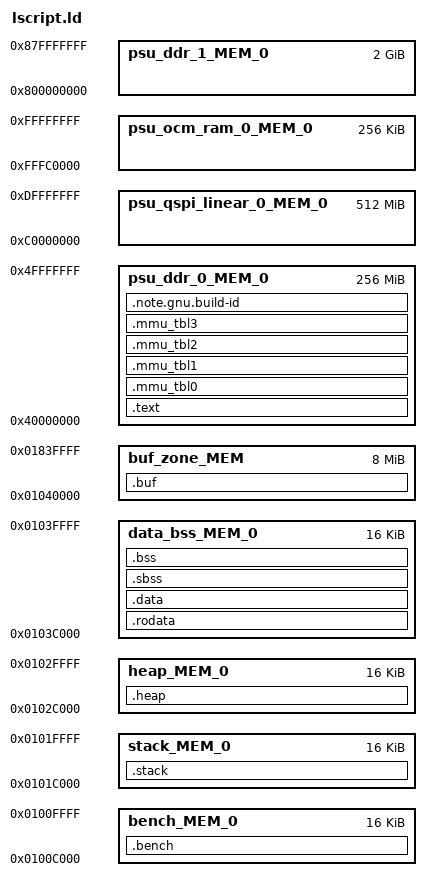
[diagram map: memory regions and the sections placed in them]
/*******************************************************************/
/*                                                                 */
/* This file is automatically generated by linker script generator.*/
/*                                                                 */
/* Version: 2018.3                                                 */
/*                                                                 */
/* Copyright (c) 2010-2019 Xilinx, Inc.  All rights reserved.      */
/*                                                                 */
/* Description : ARM v8 Linker Script                           */
/*                                                                 */
/*******************************************************************/

_STACK_SIZE = DEFINED(_STACK_SIZE) ? _STACK_SIZE : 0x2000;
_HEAP_SIZE = DEFINED(_HEAP_SIZE) ? _HEAP_SIZE : 0x2000;

_EL0_STACK_SIZE = DEFINED(_EL0_STACK_SIZE) ? _EL0_STACK_SIZE : 1024;
_EL1_STACK_SIZE = DEFINED(_EL1_STACK_SIZE) ? _EL1_STACK_SIZE : 2048;
_EL2_STACK_SIZE = DEFINED(_EL2_STACK_SIZE) ? _EL2_STACK_SIZE : 1024;
_BUF_SIZE = 0x200000;

/* Define Memories in the system */

MEMORY
{
    bench_MEM_0     : ORIGIN = 0x100C000, LENGTH = 0x4000
    stack_MEM_0     : ORIGIN = 0x101C000, LENGTH = 0x4000
    heap_MEM_0      : ORIGIN = 0x102C000, LENGTH = 0x4000
    data_bss_MEM_0  : ORIGIN = 0x103C000, LENGTH = 0x4000
    buf_zone_MEM    : ORIGIN = 0x1040000, LENGTH = 0x800000
    psu_ddr_0_MEM_0 : ORIGIN = 0x40000000, LENGTH = 0x10000000
    psu_ddr_1_MEM_0 : ORIGIN = 0x800000000, LENGTH = 0x80000000
    psu_ocm_ram_0_MEM_0 : ORIGIN = 0xFFFC0000, LENGTH = 0x40000
    psu_qspi_linear_0_MEM_0 : ORIGIN = 0xC0000000, LENGTH = 0x20000000
}

/* Specify the default entry point to the program */

ENTRY(_vector_table)

/* Define the sections, and where they are mapped in memory */

SECTIONS
{
.bench : {
    . = ALIGN(16384);
    __bench_start = .;
    *(.bench)
    *(.bench.*)
    __bench_end = .;
} > bench_MEM_0

.text : {
    . = ALIGN(4096);
    __text_start = .;
   KEEP (*(.vectors))
   *(.boot)
   *(.text)
   *(.text.*)
   __text_end = .;
} > psu_ddr_0_MEM_0


.rodata : {
   . = ALIGN(64);
   __rodata_start = .;
   *(.rodata)
   *(.rodata.*)
   __rodata_end = .;
} > data_bss_MEM_0

.data : {
   . = ALIGN(64);
   __data_start = .;
   *(.data)
   *(.data.*)
   __data_end = .;
} > data_bss_MEM_0

.mmu_tbl0 : {
    . = ALIGN(4096);
   __mmu_tbl0_start = .;
   *(.mmu_tbl0)
   __mmu_tbl0_end = .;
} > psu_ddr_0_MEM_0

.mmu_tbl1 : {
    . = ALIGN(4096);
   __mmu_tbl1_start = .;
   *(.mmu_tbl1)
   __mmu_tbl1_end = .;
} > psu_ddr_0_MEM_0

.mmu_tbl2  : {
    . = ALIGN(4096);
   __mmu_tbl2_start = .;
   *(.mmu_tbl2)
   __mmu_tbl2_end = .;
} > psu_ddr_0_MEM_0

.mmu_tbl3  : {
    . = ALIGN(4096);
   __mmu_tbl3_start = .;
   *(.mmu_tbl3)
   __mmu_tbl3_end = .;
} > psu_ddr_0_MEM_0

.note.gnu.build-id : {
   KEEP (*(.note.gnu.build-id))
} > psu_ddr_0_MEM_0

.buf (NOLOAD) : {
	. = ALIGN(4096);
	__buf_start_0 = .;
	. += _BUF_SIZE;
    __buf_start_1 = .;
	. += _BUF_SIZE;
    __buf_start_2 = .;
	. += _BUF_SIZE;
    __buf_start_3 = .;
	. += _BUF_SIZE;
	__buf_end = .;
} > buf_zone_MEM

.sbss (NOLOAD) : {
   . = ALIGN(64);
   __sbss_start = .;
   *(.sbss)
   *(.sbss.*)
   *(.gnu.linkonce.sb.*)
   . = ALIGN(64);
   __sbss_end = .;
} > data_bss_MEM_0

.bss (NOLOAD) : {
   . = ALIGN(64);
   __bss_start__ = .;
   *(.bss)
   *(.bss.*)
   *(.gnu.linkonce.b.*)
   *(COMMON)
   . = ALIGN(64);
   __bss_end__ = .;
} > data_bss_MEM_0

/* Generate Stack and Heap definitions */

.heap (NOLOAD) : {
   . = ALIGN(64);
   __heap_start = .;
   _heap = .;
   HeapBase = .;
   _heap_start = .;
   . += _HEAP_SIZE;
   _heap_end = .;
   HeapLimit = .;
} > heap_MEM_0

.stack (NOLOAD) : {
   . = ALIGN(64);
   __stack_start = .;
   _el3_stack_end = .;
   . += _STACK_SIZE;
   __el3_stack = .;
   _el2_stack_end = .;
   . += _EL2_STACK_SIZE;
   . = ALIGN(64);
   __el2_stack = .;
   _el1_stack_end = .;
   . += _EL1_STACK_SIZE;
   . = ALIGN(64);
   __el1_stack = .;
   _el0_stack_end = .;
   . += _EL0_STACK_SIZE;
   . = ALIGN(64);
   __el0_stack = .;
} > stack_MEM_0

_end = .;
}
